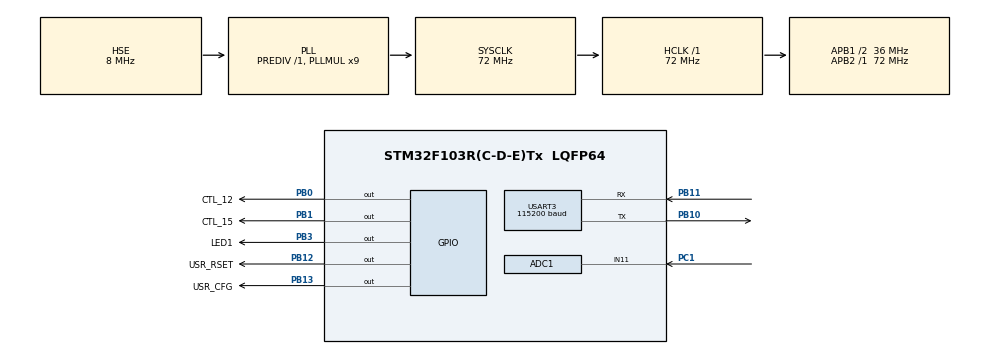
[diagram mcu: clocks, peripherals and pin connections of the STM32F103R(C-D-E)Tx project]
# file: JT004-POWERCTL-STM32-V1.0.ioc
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ADC1.Channel-1\#ChannelRegularConversion=ADC_CHANNEL_11
ADC1.NbrOfConversionFlag=1
ADC1.Rank-1\#ChannelRegularConversion=1
ADC1.SamplingTime-1\#ChannelRegularConversion=ADC_SAMPLETIME_1CYCLE_5
ADC1.master=1
IWDG.Prescaler=IWDG_PRESCALER_32
IWDG.Reload=2499
Mcu.Family=STM32F1
Mcu.Name=STM32F103R(C-D-E)Tx
Mcu.Package=LQFP64
NVIC.PriorityGroup=NVIC_PRIORITYGROUP_4
NVIC.TIM2_IRQn=true\:0\:0\:false\:false\:true\:true\:true\:true
NVIC.USART3_IRQn=true\:2\:0\:true\:false\:true\:true\:true\:true
PA13.Mode=Serial_Wire
PA13.Signal=SYS_JTMS-SWDIO
PA14.Mode=Serial_Wire
PA14.Signal=SYS_JTCK-SWCLK
PB0.GPIO_Label=CTL_12
PB0.PinState=GPIO_PIN_RESET
PB0.Signal=GPIO_Output
PB1.GPIO_Label=CTL_15
PB1.PinState=GPIO_PIN_RESET
PB1.Signal=GPIO_Output
PB10.Mode=Asynchronous
PB10.Signal=USART3_TX
PB11.Mode=Asynchronous
PB11.Signal=USART3_RX
PB12.GPIO_Label=USR_RSET
PB12.PinState=GPIO_PIN_SET
PB12.Signal=GPIO_Output
PB13.GPIO_Label=USR_CFG
PB13.PinState=GPIO_PIN_SET
PB13.Signal=GPIO_Output
PB3.GPIO_Label=LED1
PB3.Signal=GPIO_Output
PC1.Signal=ADCx_IN11
PD0-OSC_IN.Mode=HSE-External-Oscillator
PD0-OSC_IN.Signal=RCC_OSC_IN
PD1-OSC_OUT.Mode=HSE-External-Oscillator
PD1-OSC_OUT.Signal=RCC_OSC_OUT
ProjectManager.HeapSize=0x200
ProjectManager.StackSize=0x400
ProjectManager.TargetToolchain=CMake
RCC.ADCPresc=RCC_ADCPCLK2_DIV6
RCC.AHBFreq_Value=72000000
RCC.APB1CLKDivider=RCC_HCLK_DIV2
RCC.APB1Freq_Value=36000000
RCC.APB1TimFreq_Value=72000000
RCC.APB2Freq_Value=72000000
RCC.APB2TimFreq_Value=72000000
RCC.HCLKFreq_Value=72000000
RCC.PLLMUL=RCC_PLL_MUL9
RCC.PLLSourceVirtual=RCC_PLLSOURCE_HSE
RCC.SYSCLKFreq_VALUE=72000000
RCC.SYSCLKSource=RCC_SYSCLKSOURCE_PLLCLK
RCC.USBFreq_Value=72000000
SH.ADCx_IN11.0=ADC1_IN11,IN11
TIM2.Period=1000-1
TIM2.Prescaler=36-1
USART3.BaudRate=115200
USART3.VirtualMode=VM_ASYNC
VP_IWDG_VS_IWDG.Mode=IWDG_Activate
VP_TIM2_VS_ClockSourceINT.Mode=Internal
board=custom

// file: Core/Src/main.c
/* USER CODE BEGIN Header */
/**
  ******************************************************************************
  * @file           : main.c
  * @brief          : Main program body
  ******************************************************************************
  * @attention
  *
  * Copyright (c) 2026 STMicroelectronics.
  * All rights reserved.
  *
  * This software is licensed under terms that can be found in the LICENSE file
  * in the root directory of this software component.
  * If no LICENSE file comes with this software, it is provided AS-IS.
  *
  ******************************************************************************
  */
/* USER CODE END Header */
#include "main.h"
#include "adc.h"
#include "iwdg.h"
#include "tim.h"
#include "usart.h"
#include "gpio.h"

/* USER CODE BEGIN Includes */
#include "app_task.h"
/* USER CODE END Includes */

void SystemClock_Config(void);

int main(void)
{

  /* USER CODE BEGIN 1 */
  __enable_irq(); /* Bootloader跳转前执行了__disable_irq()，PRIMASK会带到APP，必须在此恢复，否则SysTick被屏蔽、HAL_Delay永久卡死 */
  /* USER CODE END 1 */

  /* MCU Configuration--------------------------------------------------------*/

  /* Reset of all peripherals, Initializes the Flash interface and the Systick. */
  HAL_Init();

  /* Configure the system clock */
  SystemClock_Config();

  /* Initialize all configured peripherals */
  MX_GPIO_Init();
  MX_USART3_UART_Init();
  MX_TIM2_Init();
 // MX_IWDG_Init();
  MX_ADC1_Init();
  /* USER CODE BEGIN 2 */
  //APP层
  task_Start();
  /* USER CODE END 2 */

  /* Infinite loop */
  while (1)
  {

  }
}

void SystemClock_Config(void)
{
  RCC_OscInitTypeDef RCC_OscInitStruct = {0};
  RCC_ClkInitTypeDef RCC_ClkInitStruct = {0};
  RCC_PeriphCLKInitTypeDef PeriphClkInit = {0};

  /** Initializes the RCC Oscillators according to the specified parameters
  * in the RCC_OscInitTypeDef structure.
  */
  RCC_OscInitStruct.OscillatorType = RCC_OSCILLATORTYPE_LSI|RCC_OSCILLATORTYPE_HSE;
  RCC_OscInitStruct.HSEState = RCC_HSE_ON;
  RCC_OscInitStruct.HSEPredivValue = RCC_HSE_PREDIV_DIV1;
  RCC_OscInitStruct.HSIState = RCC_HSI_ON;
  RCC_OscInitStruct.LSIState = RCC_LSI_ON;
  RCC_OscInitStruct.PLL.PLLState = RCC_PLL_ON;
  RCC_OscInitStruct.PLL.PLLSource = RCC_PLLSOURCE_HSE;
  RCC_OscInitStruct.PLL.PLLMUL = RCC_PLL_MUL9;
  if (HAL_RCC_OscConfig(&RCC_OscInitStruct) != HAL_OK)
  {
    Error_Handler();
  }

  /** Initializes the CPU, AHB and APB buses clocks
  */
  RCC_ClkInitStruct.ClockType = RCC_CLOCKTYPE_HCLK|RCC_CLOCKTYPE_SYSCLK
                              |RCC_CLOCKTYPE_PCLK1|RCC_CLOCKTYPE_PCLK2;
  RCC_ClkInitStruct.SYSCLKSource = RCC_SYSCLKSOURCE_PLLCLK;
  RCC_ClkInitStruct.AHBCLKDivider = RCC_SYSCLK_DIV1;
  RCC_ClkInitStruct.APB1CLKDivider = RCC_HCLK_DIV2;
  RCC_ClkInitStruct.APB2CLKDivider = RCC_HCLK_DIV1;

  if (HAL_RCC_ClockConfig(&RCC_ClkInitStruct, FLASH_LATENCY_2) != HAL_OK)
  {
    Error_Handler();
  }
  PeriphClkInit.PeriphClockSelection = RCC_PERIPHCLK_ADC;
  PeriphClkInit.AdcClockSelection = RCC_ADCPCLK2_DIV6;
  if (HAL_RCCEx_PeriphCLKConfig(&PeriphClkInit) != HAL_OK)
  {
    Error_Handler();
  }
}

void Error_Handler(void)
{
  __disable_irq();
  while (1)
  {
  }
}
